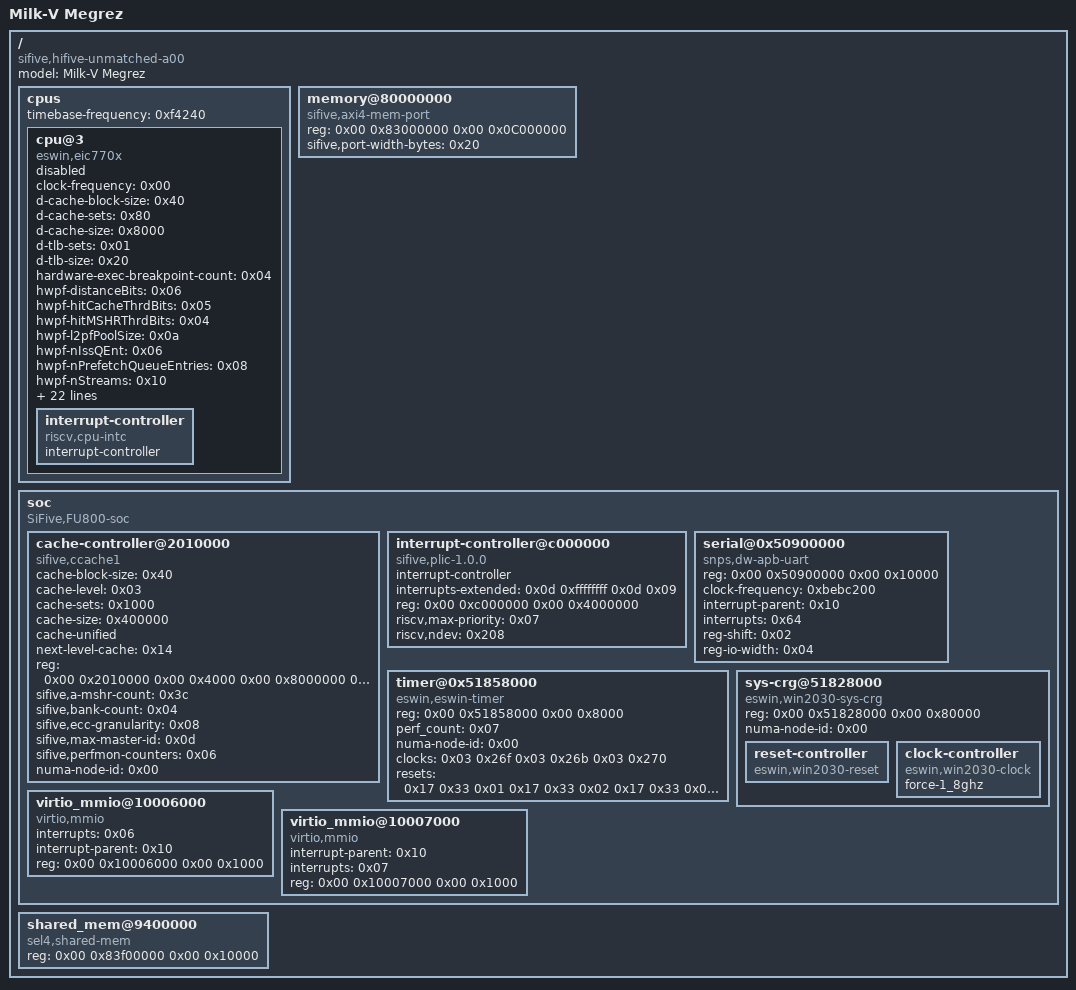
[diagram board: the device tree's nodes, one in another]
/dts-v1/;

/ {
	#address-cells = <0x02>;
	#size-cells = <0x02>;
	compatible = "sifive,hifive-unmatched-a00\0sifive,fu740-c000\0sifive,fu740\0eswin,eic7700";
	model = "Milk-V Megrez";
	
	cpus {
		#address-cells = <0x01>;
		#size-cells = <0x00>;
		timebase-frequency = <0xf4240>;
		
		cpu@3 {
			clock-frequency = <0x00>;
			compatible = "eswin,eic770x\0riscv";
			d-cache-block-size = <0x40>;
			d-cache-sets = <0x80>;
			d-cache-size = <0x8000>;
			d-tlb-sets = <0x01>;
			d-tlb-size = <0x20>;
			device_type = "cpu";
			hardware-exec-breakpoint-count = <0x04>;
			hwpf-distanceBits = <0x06>;
			hwpf-hitCacheThrdBits = <0x05>;
			hwpf-hitMSHRThrdBits = <0x04>;
			hwpf-l2pfPoolSize = <0x0a>;
			hwpf-nIssQEnt = <0x06>;
			hwpf-nPrefetchQueueEntries = <0x08>;
			hwpf-nStreams = <0x10>;
			hwpf-qFullnessThrdBits = <0x04>;
			hwpf-windowBits = <0x06>;
			i-cache-block-size = <0x40>;
			i-cache-sets = <0x80>;
			i-cache-size = <0x8000>;
			i-tlb-sets = <0x01>;
			i-tlb-size = <0x20>;
			mmu-type = "riscv,sv48";
			next-level-cache = <0x0a>;
			reg = <0x03>;
			riscv,isa = "rv64imafdch_zicsr_zifencei_zba_zbb_sscofpmf";
			riscv,pmpgranularity = <0x1000>;
			riscv,pmpregions = <0x08>;
			sifive,buserror = <0x0b>;
			status = "disabled";
			timebase-frequency = <0xf4240>;
			tlb-split;
			numa-node-id = <0x00>;
			clocks = <0x03 0x1f7>;
			operating-points-v2 = <0x04>;
			#cooling-cells = <0x02>;
			dynamic-power-coefficient = <0x320>;
			cpu-idle-states = <0x05>;
			phandle = <0x9a>;

			interrupt-controller {
				#interrupt-cells = <0x01>;
				compatible = "riscv,cpu-intc";
				interrupt-controller;
				phandle = <0x0f>;
			};
		};
	};
	
	memory@80000000 {
		compatible = "sifive,axi4-mem-port\0sifive,axi4-port\0sifive,mem-port";
		device_type = "memory";
		reg = <0x00 0x83000000 0x00 0x0C000000>;
		sifive,port-width-bytes = <0x20>;
		phandle = <0x14>;
	};
	
	soc {
		#address-cells = <0x02>;
		#size-cells = <0x02>;
		compatible = "SiFive,FU800-soc\0fu800-soc\0sifive-soc\0simple-bus";
		ranges;

		cache-controller@2010000 {
			cache-block-size = <0x40>;
			cache-level = <0x03>;
			cache-sets = <0x1000>;
			cache-size = <0x400000>;
			cache-unified;
			compatible = "sifive,ccache1\0cache\0sifive,fu740-c000-ccache";
			// interrupt-parent = <0x10>;
			// interrupts = <0x01 0x03 0x04 0x02>;
			next-level-cache = <0x14>;
			reg = <0x00 0x2010000 0x00 0x4000 0x00 0x8000000 0x00 0x400000>;
			reg-names = "control\0sideband";
			sifive,a-mshr-count = <0x3c>;
			sifive,bank-count = <0x04>;
			sifive,ecc-granularity = <0x08>;
			sifive,max-master-id = <0x0d>;
			sifive,perfmon-counters = <0x06>;
			numa-node-id = <0x00>;
			phandle = <0x15>;
		};
		
		interrupt-controller@c000000 {
			#interrupt-cells = <0x01>;
			compatible = "sifive,plic-1.0.0";
			interrupt-controller;
			interrupts-extended = <0x0d 0xffffffff 0x0d 0x09>;
			reg = <0x00 0xc000000 0x00 0x4000000>;
			reg-names = "control";
			riscv,max-priority = <0x07>;
			riscv,ndev = <0x208>;
			phandle = <0x10>;
		};

		serial@0x50900000 {
			compatible = "snps,dw-apb-uart";
			reg = <0x00 0x50900000 0x00 0x10000>;
			clock-frequency = <0xbebc200>;
			interrupt-parent = <0x10>;
			interrupts = <0x64>;
			reg-shift = <0x02>;
			reg-io-width = <0x04>;
			status = "okay";
		};

		timer@0x51858000 {
			compatible = "eswin,eswin-timer";
			#address-cells = <0x02>;
			#size-cells = <0x02>;
			reg = <0x00 0x51858000 0x00 0x8000>;
			perf_count = <0x07>;
			numa-node-id = <0x00>;
			clock-names = "pclk\0timer_aclk\0timer3_clk8";
			clocks = <0x03 0x26f 0x03 0x26b 0x03 0x270>;
			resets = <0x17 0x33 0x01 0x17 0x33 0x02 0x17 0x33 0x04 0x17 0x33 0x08 0x17 0x33 0x10 0x17 0x33 0x20 0x17 0x33 0x40 0x17 0x33 0x80 0x17 0x33 0x100>;
			reset-names = "trst0\0trst1\0trst2\0trst3\0trst4\0trst5\0trst6\0trst7\0prst";
			status = "okay";
			phandle = <0x18f>;
		};
		
		sys-crg@51828000 {
			compatible = "eswin,win2030-sys-crg\0syscon\0simple-mfd";
			reg = <0x00 0x51828000 0x00 0x80000>;
			numa-node-id = <0x00>;
			phandle = <0x16>;

			reset-controller {
				compatible = "eswin,win2030-reset";
				#reset-cells = <0x02>;
				status = "okay";
				phandle = <0x18>;
			};

			clock-controller {
				compatible = "eswin,win2030-clock";
				#clock-cells = <0x01>;
				status = "okay";
				force-1_8ghz;
				phandle = <0x03>;
			};
		};

		virtio_mmio@10006000 {
			interrupts = <0x06>;
			interrupt-parent = <0x10>;
			reg = <0x00 0x10006000 0x00 0x1000>;
			compatible = "virtio,mmio";
		};
		
		// virtio console
		virtio_mmio@10007000 {
			interrupt-parent = <0x10>;
			interrupts = <0x07>;
			reg = <0x00 0x10007000 0x00 0x1000>;
			compatible = "virtio,mmio";
		};
	};

	// Shared memory region for VirtIO vrings/payload
	shared_mem@9400000 {
		compatible = "sel4,shared-mem";
		reg = <0x00 0x83f00000 0x00 0x10000>;
	};
	
};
